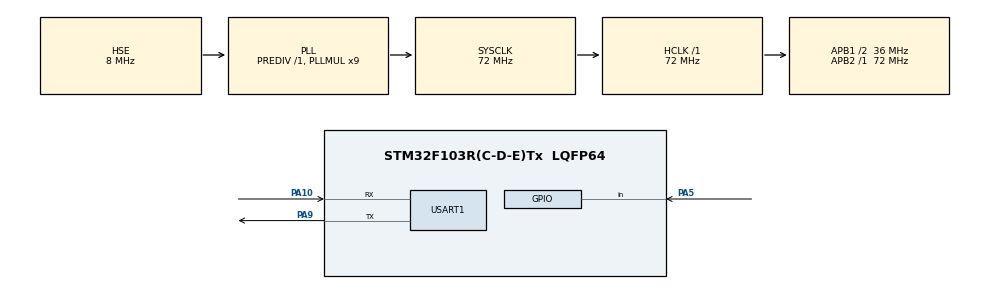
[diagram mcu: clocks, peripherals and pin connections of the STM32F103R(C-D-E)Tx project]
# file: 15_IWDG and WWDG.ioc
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IWDG.Prescaler=IWDG_PRESCALER_16
Mcu.Family=STM32F1
Mcu.Name=STM32F103R(C-D-E)Tx
Mcu.Package=LQFP64
NVIC.PriorityGroup=NVIC_PRIORITYGROUP_4
PA10.Mode=Asynchronous
PA10.Signal=USART1_RX
PA13.Mode=JTAG_5_pins
PA13.Signal=SYS_JTMS-SWDIO
PA14.Mode=JTAG_5_pins
PA14.Signal=SYS_JTCK-SWCLK
PA15.Mode=JTAG_5_pins
PA15.Signal=SYS_JTDI
PA5.GPIO_PuPd=GPIO_PULLUP
PA5.Signal=GPIO_Input
PA9.Mode=Asynchronous
PA9.Signal=USART1_TX
PB3.Mode=JTAG_5_pins
PB3.Signal=SYS_JTDO-TRACESWO
PB4.Mode=JTAG_5_pins
PB4.Signal=SYS_NJTRST
PD0-OSC_IN.Mode=HSE-External-Oscillator
PD0-OSC_IN.Signal=RCC_OSC_IN
PD1-OSC_OUT.Mode=HSE-External-Oscillator
PD1-OSC_OUT.Signal=RCC_OSC_OUT
ProjectManager.HeapSize=0x200
ProjectManager.StackSize=0x400
ProjectManager.TargetToolchain=STM32CubeIDE
RCC.AHBFreq_Value=72000000
RCC.APB1CLKDivider=RCC_HCLK_DIV2
RCC.APB1Freq_Value=36000000
RCC.APB1TimFreq_Value=72000000
RCC.APB2Freq_Value=72000000
RCC.APB2TimFreq_Value=72000000
RCC.HCLKFreq_Value=72000000
RCC.PLLMUL=RCC_PLL_MUL9
RCC.PLLSourceVirtual=RCC_PLLSOURCE_HSE
RCC.SYSCLKFreq_VALUE=72000000
RCC.SYSCLKSource=RCC_SYSCLKSOURCE_PLLCLK
RCC.USBFreq_Value=72000000
USART1.VirtualMode=VM_ASYNC
VP_IWDG_VS_IWDG.Mode=IWDG_Activate
VP_WWDG_VS_WWDG.Mode=WWDG_Activate
WWDG.Counter=127
WWDG.Prescaler=WWDG_PRESCALER_8
WWDG.Window=80
board=custom

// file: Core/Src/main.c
/* USER CODE BEGIN Header */
/**
  ******************************************************************************
  * @file           : main.c
  * @brief          : Main program body
  ******************************************************************************
  * @attention
  *
  * Copyright (c) 2022 STMicroelectronics.
  * All rights reserved.
  *
  * This software is licensed under terms that can be found in the LICENSE file
  * in the root directory of this software component.
  * If no LICENSE file comes with this software, it is provided AS-IS.
  *
  ******************************************************************************
  */
/* USER CODE END Header */
#include "main.h"

/* USER CODE BEGIN Includes */
#include "stdio_usart.h"
/* USER CODE END Includes */

/* USER CODE BEGIN PD */
// for using the code of each watchdog, uncomment it's name definition and comment the other one.
//#define  useIWDG
#define  useWWDG
/* USER CODE END PD */

 IWDG_HandleTypeDef hiwdg;

UART_HandleTypeDef huart1;

WWDG_HandleTypeDef hwwdg;

void SystemClock_Config(void);
static void MX_GPIO_Init(void);
static void MX_IWDG_Init(void);
static void MX_USART1_UART_Init(void);
static void MX_WWDG_Init(void);
/* USER CODE BEGIN PFP */
void show_reset_sources (void);
/* USER CODE END PFP */

int main(void)
{

  /* MCU Configuration--------------------------------------------------------*/

  /* Reset of all peripherals, Initializes the Flash interface and the Systick. */
  HAL_Init();

  /* Configure the system clock */
  SystemClock_Config();

  /* Initialize all configured peripherals */
  MX_GPIO_Init();
  MX_IWDG_Init();
  MX_USART1_UART_Init();
  MX_WWDG_Init();
  /* USER CODE BEGIN 2 */
  RetargetInit(&huart1);				// initializing the stdio retargetting

  show_reset_sources();					// print the reset sources
  __HAL_RCC_CLEAR_RESET_FLAGS();		// clear the reset flags

  uint32_t count = 0;					// variable for counting
  uint32_t i = 0;						// variable for timing
  /* USER CODE END 2 */

  /* Infinite loop */
  /* USER CODE BEGIN WHILE */
  while (1)
  {
	  /*******************			IWDG		  *******************/
#ifdef useIWDG
	  /* if PA5 is pressed, then IWDG counter will be reset */
	  if (HAL_GPIO_ReadPin(GPIOA, GPIO_PIN_5) == 0)
	  {
		  HAL_IWDG_Refresh(&hiwdg);
	  }

	  /* printing the count value nearly every 145 miliseconds */
	  i++;
	  if(i > 86957)
	  {
		  i = 0;
		  printf("count is: %lu\r\n", count);
		  count++;
	  }

	  // To prevent WWDG reset, when using IWDG
	  if(hwwdg.Instance->CR <= (255 - (hwwdg.Init.Counter - hwwdg.Init.Window)))
  	  {
	  	  HAL_WWDG_Refresh(&hwwdg);
  	  }
#endif

	  /*******************			WWDG		  *******************/
#ifdef useWWDG
	  HAL_IWDG_Refresh(&hiwdg);			// the IWDG will not reset the MCU

	  /* printing the counter nearly every second */
	  i++;
	  if(i > 600000)
	  {
		  count++;
		  i = 0;
		  printf("count is: %lu\r\n", count);
	  }

	  /* if push button connected to PB0 is pushed, then the WWDG counter wont be reset */
	  if(HAL_GPIO_ReadPin(GPIOA, GPIO_PIN_5) == 0)
	  {
		  if(hwwdg.Instance->CR <= (255 - (hwwdg.Init.Counter - hwwdg.Init.Window)))
	  	  {
		  	  HAL_WWDG_Refresh(&hwwdg);
	  	  }
	  }
#endif
    /* USER CODE END WHILE */

  }
}

void SystemClock_Config(void)
{
  RCC_OscInitTypeDef RCC_OscInitStruct = {0};
  RCC_ClkInitTypeDef RCC_ClkInitStruct = {0};

  /** Initializes the RCC Oscillators according to the specified parameters
  * in the RCC_OscInitTypeDef structure.
  */
  RCC_OscInitStruct.OscillatorType = RCC_OSCILLATORTYPE_LSI|RCC_OSCILLATORTYPE_HSE;
  RCC_OscInitStruct.HSEState = RCC_HSE_ON;
  RCC_OscInitStruct.HSEPredivValue = RCC_HSE_PREDIV_DIV1;
  RCC_OscInitStruct.HSIState = RCC_HSI_ON;
  RCC_OscInitStruct.LSIState = RCC_LSI_ON;
  RCC_OscInitStruct.PLL.PLLState = RCC_PLL_ON;
  RCC_OscInitStruct.PLL.PLLSource = RCC_PLLSOURCE_HSE;
  RCC_OscInitStruct.PLL.PLLMUL = RCC_PLL_MUL9;
  if (HAL_RCC_OscConfig(&RCC_OscInitStruct) != HAL_OK)
  {
    Error_Handler();
  }

  /** Initializes the CPU, AHB and APB buses clocks
  */
  RCC_ClkInitStruct.ClockType = RCC_CLOCKTYPE_HCLK|RCC_CLOCKTYPE_SYSCLK
                              |RCC_CLOCKTYPE_PCLK1|RCC_CLOCKTYPE_PCLK2;
  RCC_ClkInitStruct.SYSCLKSource = RCC_SYSCLKSOURCE_PLLCLK;
  RCC_ClkInitStruct.AHBCLKDivider = RCC_SYSCLK_DIV1;
  RCC_ClkInitStruct.APB1CLKDivider = RCC_HCLK_DIV2;
  RCC_ClkInitStruct.APB2CLKDivider = RCC_HCLK_DIV1;

  if (HAL_RCC_ClockConfig(&RCC_ClkInitStruct, FLASH_LATENCY_2) != HAL_OK)
  {
    Error_Handler();
  }
}

static void MX_IWDG_Init(void)
{

  hiwdg.Instance = IWDG;
  hiwdg.Init.Prescaler = IWDG_PRESCALER_16;
  hiwdg.Init.Reload = 4095;
  if (HAL_IWDG_Init(&hiwdg) != HAL_OK)
  {
    Error_Handler();
  }

}

static void MX_USART1_UART_Init(void)
{

  huart1.Instance = USART1;
  huart1.Init.BaudRate = 115200;
  huart1.Init.WordLength = UART_WORDLENGTH_8B;
  huart1.Init.StopBits = UART_STOPBITS_1;
  huart1.Init.Parity = UART_PARITY_NONE;
  huart1.Init.Mode = UART_MODE_TX_RX;
  huart1.Init.HwFlowCtl = UART_HWCONTROL_NONE;
  huart1.Init.OverSampling = UART_OVERSAMPLING_16;
  if (HAL_UART_Init(&huart1) != HAL_OK)
  {
    Error_Handler();
  }

}

static void MX_WWDG_Init(void)
{

  hwwdg.Instance = WWDG;
  hwwdg.Init.Prescaler = WWDG_PRESCALER_8;
  hwwdg.Init.Window = 80;
  hwwdg.Init.Counter = 127;
  hwwdg.Init.EWIMode = WWDG_EWI_DISABLE;
  if (HAL_WWDG_Init(&hwwdg) != HAL_OK)
  {
    Error_Handler();
  }

}

static void MX_GPIO_Init(void)
{
  GPIO_InitTypeDef GPIO_InitStruct = {0};

  /* GPIO Ports Clock Enable */
  __HAL_RCC_GPIOD_CLK_ENABLE();
  __HAL_RCC_GPIOA_CLK_ENABLE();
  __HAL_RCC_GPIOB_CLK_ENABLE();

  /*Configure GPIO pin : PA5 */
  GPIO_InitStruct.Pin = GPIO_PIN_5;
  GPIO_InitStruct.Mode = GPIO_MODE_INPUT;
  GPIO_InitStruct.Pull = GPIO_PULLUP;
  HAL_GPIO_Init(GPIOA, &GPIO_InitStruct);

}

/* USER CODE BEGIN 4 */
void show_reset_sources (void)
{
	if(__HAL_RCC_GET_FLAG(RCC_FLAG_SFTRST))
		printf("reset source was software reset\r\n");
	else if(__HAL_RCC_GET_FLAG(RCC_FLAG_LPWRRST))
		printf("reset source was Low Power reset\r\n");
	else if(__HAL_RCC_GET_FLAG(RCC_FLAG_PORRST))
		printf("reset source was POR/PDR\r\n");
	else if(__HAL_RCC_GET_FLAG(RCC_FLAG_WWDGRST))
		printf("reset source was Window Watchdog\r\n");
	else if(__HAL_RCC_GET_FLAG(RCC_FLAG_IWDGRST))
		printf("reset source was Independent Watchdog\r\n");
	else if(__HAL_RCC_GET_FLAG(RCC_FLAG_PINRST))
		printf("reset source was reset pin\r\n");

	printf("\r\nReset sources:\r\nPIN: %d\r\nIWDG: %d\r\nWWDG: %d\r\nSFT: %d\r\nLPW: %d\r\nPOR/PDR: %d\r\n\r\n\r\n",
	(__HAL_RCC_GET_FLAG(RCC_FLAG_PINRST) != 0), (__HAL_RCC_GET_FLAG(RCC_FLAG_IWDGRST) != 0), (__HAL_RCC_GET_FLAG(RCC_FLAG_WWDGRST) != 0),
	(__HAL_RCC_GET_FLAG(RCC_FLAG_SFTRST) != 0), (__HAL_RCC_GET_FLAG(RCC_FLAG_LPWRRST) != 0), (__HAL_RCC_GET_FLAG(RCC_FLAG_PORRST) != 0));
}
/* USER CODE END 4 */

void Error_Handler(void)
{
  __disable_irq();
  while (1)
  {
  }
}
